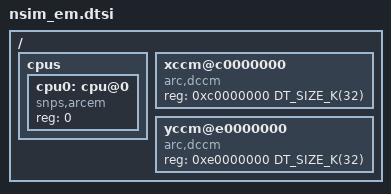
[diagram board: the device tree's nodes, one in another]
/*
 * Copyright (c) 2019, Synopsys, Inc. All rights reserved.
 *
 * SPDX-License-Identifier: Apache-2.0
 */

/dts-v1/;
#include <mem.h>
#include "nsim.dtsi"

/ {
	cpus {
		#address-cells = <1>;
		#size-cells = <0>;

		cpu0: cpu@0 {
			device_type = "cpu";
			compatible = "snps,arcem";
			reg = <0>;
		};
	};

	xccm@c0000000 {
		compatible = "arc,dccm";
		reg = <0xc0000000 DT_SIZE_K(32)>;
	};

	yccm@e0000000 {
		compatible = "arc,dccm";
		reg = <0xe0000000 DT_SIZE_K(32)>;
	};
};
